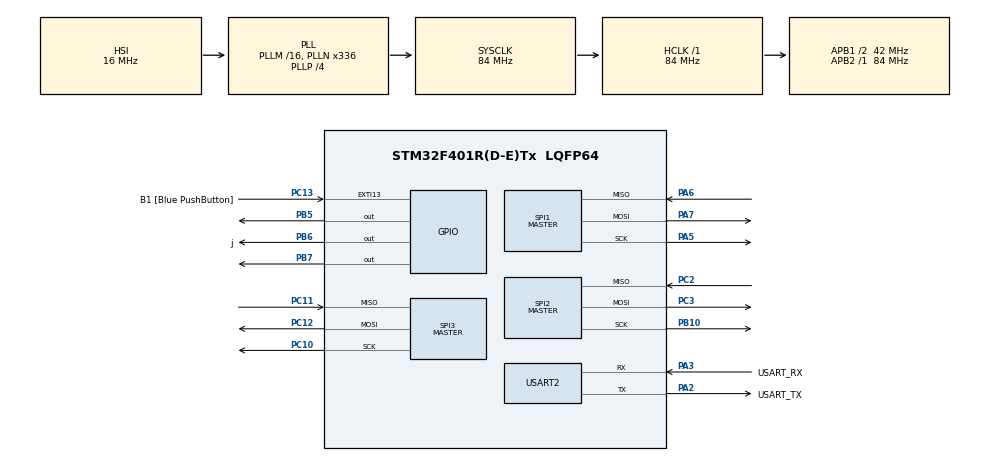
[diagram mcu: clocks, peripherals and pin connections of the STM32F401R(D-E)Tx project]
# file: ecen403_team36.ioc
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Mcu.Family=STM32F4
Mcu.Name=STM32F401R(D-E)Tx
Mcu.Package=LQFP64
NVIC.PriorityGroup=NVIC_PRIORITYGROUP_0
PA13.GPIO_Label=TMS
PA13.Mode=Serial_Wire
PA13.Signal=SYS_JTMS-SWDIO
PA14.GPIO_Label=TCK
PA14.Mode=Serial_Wire
PA14.Signal=SYS_JTCK-SWCLK
PA2.GPIO_Label=USART_TX
PA2.GPIO_Mode=GPIO_MODE_AF_PP
PA2.GPIO_PuPd=GPIO_NOPULL
PA2.GPIO_Speed=GPIO_SPEED_FREQ_LOW
PA2.Mode=Asynchronous
PA2.Signal=USART2_TX
PA3.GPIO_Label=USART_RX
PA3.GPIO_Mode=GPIO_MODE_AF_PP
PA3.GPIO_PuPd=GPIO_NOPULL
PA3.GPIO_Speed=GPIO_SPEED_FREQ_LOW
PA3.Mode=Asynchronous
PA3.Signal=USART2_RX
PA5.Mode=Full_Duplex_Master
PA5.Signal=SPI1_SCK
PA6.Mode=Full_Duplex_Master
PA6.Signal=SPI1_MISO
PA7.Mode=Full_Duplex_Master
PA7.Signal=SPI1_MOSI
PB10.Mode=Full_Duplex_Master
PB10.Signal=SPI2_SCK
PB3.GPIO_Label=SWO
PB3.Signal=SYS_JTDO-SWO
PB5.GPIO_PuPd=GPIO_NOPULL
PB5.Signal=GPIO_Output
PB6.GPIO_Label=j
PB6.Signal=GPIO_Output
PB7.GPIO_PuPd=GPIO_NOPULL
PB7.Signal=GPIO_Output
PC10.Mode=Full_Duplex_Master
PC10.Signal=SPI3_SCK
PC11.Mode=Full_Duplex_Master
PC11.Signal=SPI3_MISO
PC12.Mode=Full_Duplex_Master
PC12.Signal=SPI3_MOSI
PC13-ANTI_TAMP.GPIO_Label=B1 [Blue PushButton]
PC13-ANTI_TAMP.GPIO_ModeDefaultEXTI=GPIO_MODE_IT_FALLING
PC13-ANTI_TAMP.GPIO_PuPd=GPIO_NOPULL
PC13-ANTI_TAMP.Signal=GPXTI13
PC2.Mode=Full_Duplex_Master
PC2.Signal=SPI2_MISO
PC3.Mode=Full_Duplex_Master
PC3.Signal=SPI2_MOSI
ProjectManager.HeapSize=0x200
ProjectManager.StackSize=0x400
ProjectManager.TargetToolchain=STM32CubeIDE
RCC.48MHZClocksFreq_Value=48000000
RCC.AHBFreq_Value=84000000
RCC.APB1CLKDivider=RCC_HCLK_DIV2
RCC.APB1Freq_Value=42000000
RCC.APB1TimFreq_Value=84000000
RCC.APB2Freq_Value=84000000
RCC.APB2TimFreq_Value=84000000
RCC.CortexFreq_Value=84000000
RCC.HCLKFreq_Value=84000000
RCC.HSE_VALUE=8000000
RCC.HSI_VALUE=16000000
RCC.LSE_VALUE=32768
RCC.PLLN=336
RCC.PLLP=RCC_PLLP_DIV4
RCC.PLLQ=7
RCC.SYSCLKFreq_VALUE=84000000
RCC.SYSCLKSource=RCC_SYSCLKSOURCE_PLLCLK
RCC.VCOOutputFreq_Value=336000000
SPI1.BaudRatePrescaler=SPI_BAUDRATEPRESCALER_8
SPI1.DataSize=SPI_DATASIZE_16BIT
SPI1.Direction=SPI_DIRECTION_2LINES
SPI1.Mode=SPI_MODE_MASTER
SPI1.VirtualType=VM_MASTER
SPI2.BaudRatePrescaler=SPI_BAUDRATEPRESCALER_8
SPI2.CLKPhase=SPI_PHASE_1EDGE
SPI2.CLKPolarity=SPI_POLARITY_LOW
SPI2.DataSize=SPI_DATASIZE_16BIT
SPI2.Direction=SPI_DIRECTION_2LINES
SPI2.FirstBit=SPI_FIRSTBIT_MSB
SPI2.Mode=SPI_MODE_MASTER
SPI2.VirtualType=VM_MASTER
SPI3.BaudRatePrescaler=SPI_BAUDRATEPRESCALER_8
SPI3.CLKPolarity=SPI_POLARITY_HIGH
SPI3.DataSize=SPI_DATASIZE_16BIT
SPI3.Direction=SPI_DIRECTION_2LINES
SPI3.FirstBit=SPI_FIRSTBIT_MSB
SPI3.Mode=SPI_MODE_MASTER
SPI3.VirtualType=VM_MASTER
USART2.VirtualMode=VM_ASYNC
board=NUCLEO-F401RE

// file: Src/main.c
/* USER CODE BEGIN Header */
/**
  ******************************************************************************
  * @file           : main.c
  * @brief          : Main program body
  ******************************************************************************
  * @attention
  *
  * <h2><center>&copy; Copyright (c) 2021 STMicroelectronics.
  * All rights reserved.</center></h2>
  *
  * This software component is licensed by ST under BSD 3-Clause license,
  * the "License"; You may not use this file except in compliance with the
  * License. You may obtain a copy of the License at:
  *                        opensource.org/licenses/BSD-3-Clause
  *
  ******************************************************************************
  */
/* USER CODE END Header */
#include "main.h"

 SPI_HandleTypeDef hspi1;
SPI_HandleTypeDef hspi2;
SPI_HandleTypeDef hspi3;

UART_HandleTypeDef huart2;

/* USER CODE BEGIN PV */
const uint8_t EEPROM_READ = 0b00000011;
const uint8_t EEPROM_WRITE = 0b00000010;
const uint8_t EEPROM_WRDI = 0b00000100;
const uint8_t EEPROM_WREN = 0b00000110;
const uint8_t EEPROM_RDSR = 0b00000101;
const uint8_t EEPROM_WRSR = 0b00000001;

/* USER CODE END PV */

void SystemClock_Config(void);
static void MX_GPIO_Init(void);
static void MX_USART2_UART_Init(void);
static void MX_SPI1_Init(void);
static void MX_SPI2_Init(void);
static void MX_SPI3_Init(void);

int main(void)
{
  /* USER CODE BEGIN 1 */
	char uart_buf[50]; // uart buffer for serial terminal for testing
	int uart_buf_len;
	uint16_t adc_sig [8] = {0b10000111, 0b11000111, 0b10010111, 0b11010111, 0b10100111, 0b11100111, 0b10110111, 0b11110111}; // signal for celecting ADC
	uint16_t spi_buf[16] = {0x1111, 0x2222, 0x3333, 0x4444, 0x5555, 0x6666, 0x7777, 0x8888, 0x9999, 0x0000, 0xaaaa, 0xbbbb, 0xcccc, 0xdddd, 0xeeee, 0xffff};
	 // example buffer (16 set of 16 bits)

  /* USER CODE END 1 */

  /* MCU Configuration--------------------------------------------------------*/

  /* Reset of all peripherals, Initializes the Flash interface and the Systick. */
  HAL_Init();

  /* Configure the system clock */
  SystemClock_Config();

  /* Initialize all configured peripherals */
  MX_GPIO_Init();
  MX_USART2_UART_Init();
  MX_SPI1_Init();
  MX_SPI2_Init();
  MX_SPI3_Init();
  /* USER CODE BEGIN 2 */

 while(1){

  /*
   *
   * SPI - ADC  1 start
   *
   */
  HAL_GPIO_WritePin(GPIOB, GPIO_PIN_5, GPIO_PIN_SET);
  HAL_GPIO_WritePin(GPIOB, GPIO_PIN_6, GPIO_PIN_SET);
  HAL_GPIO_WritePin(GPIOB, GPIO_PIN_7, GPIO_PIN_SET);  // high all CS pins

  HAL_GPIO_WritePin(GPIOB, GPIO_PIN_5, GPIO_PIN_RESET); // low CS1 pin (SPI1)
  HAL_Delay(100);
  for (unsigned int i = 0; i < 8; i ++){
	  HAL_SPI_Transmit(&hspi1, (uint16_t*)adc_sig, 1, 100);
	  HAL_SPI_Receive(&hspi1, (uint16_t*)spi_buf[i], 1, 100);
	  HAL_Delay(100);
	  // need flag??
  }
  HAL_GPIO_WritePin(GPIOB, GPIO_PIN_5, GPIO_PIN_SET);

  /*
   *
   * SPI - ADC 2 start
   *
   */

  HAL_GPIO_WritePin(GPIOB, GPIO_PIN_5, GPIO_PIN_SET);
  HAL_GPIO_WritePin(GPIOB, GPIO_PIN_6, GPIO_PIN_SET);
  HAL_GPIO_WritePin(GPIOB, GPIO_PIN_7, GPIO_PIN_SET);

  HAL_GPIO_WritePin(GPIOB, GPIO_PIN_6, GPIO_PIN_RESET); // low CS2 pin (SPI2)
  HAL_Delay(100);
  for (unsigned int i = 8; i < 16; i ++){
	  HAL_SPI_Transmit(&hspi2, (uint16_t*)adc_sig, 1, 100);
	  HAL_SPI_Receive(&hspi2, (uint16_t*)spi_buf[i], 1, 100);
	  HAL_Delay(100);
	  // flags needed?
  }
  HAL_GPIO_WritePin(GPIOB, GPIO_PIN_6, GPIO_PIN_SET);

  /*
   *
   * SPI - ESP32 start
   *
   */
	  HAL_GPIO_WritePin(GPIOB, GPIO_PIN_5, GPIO_PIN_SET);
	  HAL_GPIO_WritePin(GPIOB, GPIO_PIN_6, GPIO_PIN_SET);
	  HAL_GPIO_WritePin(GPIOB, GPIO_PIN_7, GPIO_PIN_SET); // high all CS pins

	  HAL_GPIO_WritePin(GPIOB, GPIO_PIN_7, GPIO_PIN_RESET); // low CS1 pin

	  HAL_SPI_Transmit(&hspi3, (uint16_t*)spi_buf, 16, 100); // each 16bit data will be divided by 2
	  HAL_SPI_Receive(&hspi3, (uint16_t*)spi_buf, 16, 100);  // because ESP32 only can 8bit communication
      HAL_GPIO_WritePin(GPIOB, GPIO_PIN_7, GPIO_PIN_SET);
      memset(spi_buf, 0, sizeof(spi_buf)); // reset buffer for deleting garbage data
}
}
void SystemClock_Config(void)
{
  RCC_OscInitTypeDef RCC_OscInitStruct = {0};
  RCC_ClkInitTypeDef RCC_ClkInitStruct = {0};

  /** Configure the main internal regulator output voltage
  */
  __HAL_RCC_PWR_CLK_ENABLE();
  __HAL_PWR_VOLTAGESCALING_CONFIG(PWR_REGULATOR_VOLTAGE_SCALE2);

  /** Initializes the RCC Oscillators according to the specified parameters
  * in the RCC_OscInitTypeDef structure.
  */
  RCC_OscInitStruct.OscillatorType = RCC_OSCILLATORTYPE_HSI;
  RCC_OscInitStruct.HSIState = RCC_HSI_ON;
  RCC_OscInitStruct.HSICalibrationValue = RCC_HSICALIBRATION_DEFAULT;
  RCC_OscInitStruct.PLL.PLLState = RCC_PLL_ON;
  RCC_OscInitStruct.PLL.PLLSource = RCC_PLLSOURCE_HSI;
  RCC_OscInitStruct.PLL.PLLM = 16;
  RCC_OscInitStruct.PLL.PLLN = 336;
  RCC_OscInitStruct.PLL.PLLP = RCC_PLLP_DIV4;
  RCC_OscInitStruct.PLL.PLLQ = 7;
  if (HAL_RCC_OscConfig(&RCC_OscInitStruct) != HAL_OK)
  {
    Error_Handler();
  }

  /** Initializes the CPU, AHB and APB buses clocks
  */
  RCC_ClkInitStruct.ClockType = RCC_CLOCKTYPE_HCLK|RCC_CLOCKTYPE_SYSCLK
                              |RCC_CLOCKTYPE_PCLK1|RCC_CLOCKTYPE_PCLK2;
  RCC_ClkInitStruct.SYSCLKSource = RCC_SYSCLKSOURCE_PLLCLK;
  RCC_ClkInitStruct.AHBCLKDivider = RCC_SYSCLK_DIV1;
  RCC_ClkInitStruct.APB1CLKDivider = RCC_HCLK_DIV2;
  RCC_ClkInitStruct.APB2CLKDivider = RCC_HCLK_DIV1;

  if (HAL_RCC_ClockConfig(&RCC_ClkInitStruct, FLASH_LATENCY_2) != HAL_OK)
  {
    Error_Handler();
  }
}

static void MX_SPI1_Init(void)
{

  /* SPI1 parameter configuration*/
  hspi1.Instance = SPI1;
  hspi1.Init.Mode = SPI_MODE_MASTER;
  hspi1.Init.Direction = SPI_DIRECTION_2LINES;
  hspi1.Init.DataSize = SPI_DATASIZE_16BIT;
  hspi1.Init.CLKPolarity = SPI_POLARITY_LOW;
  hspi1.Init.CLKPhase = SPI_PHASE_1EDGE;
  hspi1.Init.NSS = SPI_NSS_SOFT;
  hspi1.Init.BaudRatePrescaler = SPI_BAUDRATEPRESCALER_8;
  hspi1.Init.FirstBit = SPI_FIRSTBIT_MSB;
  hspi1.Init.TIMode = SPI_TIMODE_DISABLE;
  hspi1.Init.CRCCalculation = SPI_CRCCALCULATION_DISABLE;
  hspi1.Init.CRCPolynomial = 10;
  if (HAL_SPI_Init(&hspi1) != HAL_OK)
  {
    Error_Handler();
  }

}

static void MX_SPI2_Init(void)
{

  /* SPI2 parameter configuration*/
  hspi2.Instance = SPI2;
  hspi2.Init.Mode = SPI_MODE_MASTER;
  hspi2.Init.Direction = SPI_DIRECTION_2LINES;
  hspi2.Init.DataSize = SPI_DATASIZE_16BIT;
  hspi2.Init.CLKPolarity = SPI_POLARITY_LOW;
  hspi2.Init.CLKPhase = SPI_PHASE_1EDGE;
  hspi2.Init.NSS = SPI_NSS_SOFT;
  hspi2.Init.BaudRatePrescaler = SPI_BAUDRATEPRESCALER_8;
  hspi2.Init.FirstBit = SPI_FIRSTBIT_MSB;
  hspi2.Init.TIMode = SPI_TIMODE_DISABLE;
  hspi2.Init.CRCCalculation = SPI_CRCCALCULATION_DISABLE;
  hspi2.Init.CRCPolynomial = 10;
  if (HAL_SPI_Init(&hspi2) != HAL_OK)
  {
    Error_Handler();
  }

}

static void MX_SPI3_Init(void)
{

  /* SPI3 parameter configuration*/
  hspi3.Instance = SPI3;
  hspi3.Init.Mode = SPI_MODE_MASTER;
  hspi3.Init.Direction = SPI_DIRECTION_2LINES;
  hspi3.Init.DataSize = SPI_DATASIZE_16BIT;
  hspi3.Init.CLKPolarity = SPI_POLARITY_HIGH;
  hspi3.Init.CLKPhase = SPI_PHASE_1EDGE;
  hspi3.Init.NSS = SPI_NSS_SOFT;
  hspi3.Init.BaudRatePrescaler = SPI_BAUDRATEPRESCALER_8;
  hspi3.Init.FirstBit = SPI_FIRSTBIT_MSB;
  hspi3.Init.TIMode = SPI_TIMODE_DISABLE;
  hspi3.Init.CRCCalculation = SPI_CRCCALCULATION_DISABLE;
  hspi3.Init.CRCPolynomial = 10;
  if (HAL_SPI_Init(&hspi3) != HAL_OK)
  {
    Error_Handler();
  }

}

static void MX_USART2_UART_Init(void)
{

  huart2.Instance = USART2;
  huart2.Init.BaudRate = 115200;
  huart2.Init.WordLength = UART_WORDLENGTH_8B;
  huart2.Init.StopBits = UART_STOPBITS_1;
  huart2.Init.Parity = UART_PARITY_NONE;
  huart2.Init.Mode = UART_MODE_TX_RX;
  huart2.Init.HwFlowCtl = UART_HWCONTROL_NONE;
  huart2.Init.OverSampling = UART_OVERSAMPLING_16;
  if (HAL_UART_Init(&huart2) != HAL_OK)
  {
    Error_Handler();
  }

}

static void MX_GPIO_Init(void)
{
  GPIO_InitTypeDef GPIO_InitStruct = {0};

  /* GPIO Ports Clock Enable */
  __HAL_RCC_GPIOC_CLK_ENABLE();
  __HAL_RCC_GPIOA_CLK_ENABLE();
  __HAL_RCC_GPIOB_CLK_ENABLE();

  /*Configure GPIO pin Output Level */
  HAL_GPIO_WritePin(GPIOB, GPIO_PIN_5|j_Pin|GPIO_PIN_7, GPIO_PIN_RESET);

  /*Configure GPIO pin : B1_Pin */
  GPIO_InitStruct.Pin = B1_Pin;
  GPIO_InitStruct.Mode = GPIO_MODE_IT_FALLING;
  GPIO_InitStruct.Pull = GPIO_NOPULL;
  HAL_GPIO_Init(B1_GPIO_Port, &GPIO_InitStruct);

  /*Configure GPIO pins : PB5 j_Pin PB7 */
  GPIO_InitStruct.Pin = GPIO_PIN_5|j_Pin|GPIO_PIN_7;
  GPIO_InitStruct.Mode = GPIO_MODE_OUTPUT_PP;
  GPIO_InitStruct.Pull = GPIO_NOPULL;
  GPIO_InitStruct.Speed = GPIO_SPEED_FREQ_LOW;
  HAL_GPIO_Init(GPIOB, &GPIO_InitStruct);

}

void Error_Handler(void)
{
  __disable_irq();
  while (1)
  {
  }
}
